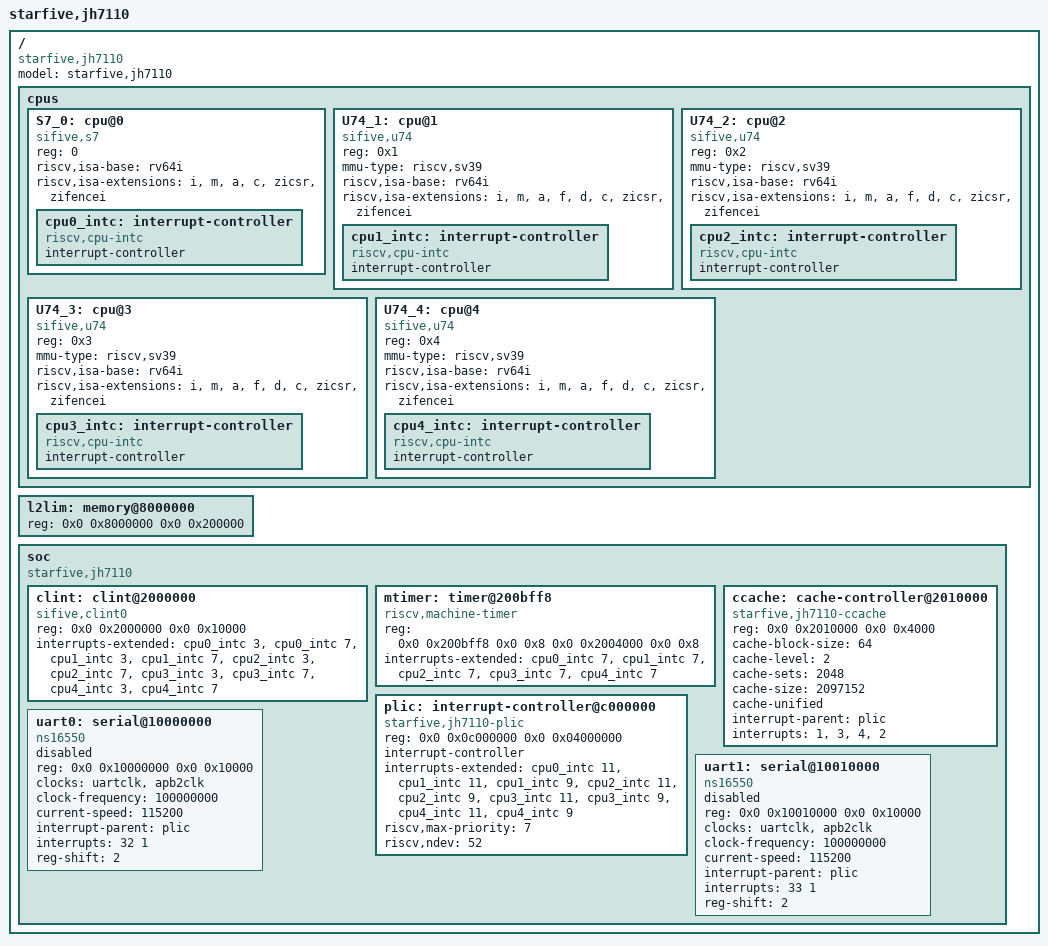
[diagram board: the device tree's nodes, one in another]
/*
 * Copyright (c) 2024 Pratik Farkase <pratik.farkase@wsisweden.com>
 * Copyright (c) 2024 Sigma Connectivity WSI AB
 *
 * SPDX-License-Identifier: Apache-2.0
 */

#include "jh7110-clk.dtsi"
#include <zephyr/dt-bindings/gpio/gpio.h>
#include <freq.h>

/ {
	compatible = "starfive,jh7110";
	#address-cells = <2>;
	#size-cells = <2>;
	model = "starfive,jh7110";

	cpus {
		#address-cells = <1>;
		#size-cells = <0>;

		S7_0: cpu@0 {
			compatible = "sifive,s7", "riscv";
			reg = <0>;
			device_type = "cpu";
			riscv,isa-base = "rv64i";
			riscv,isa-extensions = "i", "m", "a", "c", "zicsr", "zifencei";
			status = "okay";

			cpu0_intc: interrupt-controller {
				compatible = "riscv,cpu-intc";
				interrupt-controller;
				#interrupt-cells = <1>;
			};
		};

		U74_1: cpu@1 {
			compatible = "sifive,u74", "riscv";
			reg = <0x1>;
			device_type = "cpu";
			mmu-type = "riscv,sv39";
			riscv,isa-base = "rv64i";
			riscv,isa-extensions = "i", "m", "a", "f", "d", "c", "zicsr", "zifencei";

			cpu1_intc: interrupt-controller {
				compatible = "riscv,cpu-intc";
				#interrupt-cells = <1>;
				interrupt-controller;
			};
		};

		U74_2: cpu@2 {
			compatible = "sifive,u74", "riscv";
			reg = <0x2>;
			device_type = "cpu";
			mmu-type = "riscv,sv39";
			riscv,isa-base = "rv64i";
			riscv,isa-extensions = "i", "m", "a", "f", "d", "c", "zicsr", "zifencei";

			cpu2_intc: interrupt-controller {
				compatible = "riscv,cpu-intc";
				#interrupt-cells = <1>;
				interrupt-controller;
			};
		};

		U74_3: cpu@3 {
			compatible = "sifive,u74", "riscv";
			reg = <0x3>;
			device_type = "cpu";
			mmu-type = "riscv,sv39";
			riscv,isa-base = "rv64i";
			riscv,isa-extensions = "i", "m", "a", "f", "d", "c", "zicsr", "zifencei";

			cpu3_intc: interrupt-controller {
				compatible = "riscv,cpu-intc";
				#interrupt-cells = <1>;
				interrupt-controller;
			};
		};

		U74_4: cpu@4 {
			compatible = "sifive,u74", "riscv";
			reg = <0x4>;
			device_type = "cpu";
			mmu-type = "riscv,sv39";
			riscv,isa-base = "rv64i";
			riscv,isa-extensions = "i", "m", "a", "f", "d", "c", "zicsr", "zifencei";

			cpu4_intc: interrupt-controller {
				compatible = "riscv,cpu-intc";
				#interrupt-cells = <1>;
				interrupt-controller;
			};
		};
	};

	l2lim: memory@8000000 {
		reg = <0x0 0x8000000 0x0 0x200000>;
		device_type = "memory";
	};

	soc {
		compatible = "starfive,jh7110", "simple-bus";
		ranges;
		#address-cells = <2>;
		#size-cells = <2>;
		#clock-cells = <1>;

		clint: clint@2000000 {
			compatible = "sifive,clint0";
			reg = <0x0 0x2000000 0x0 0x10000>;
			interrupts-extended = <&cpu0_intc 3 &cpu0_intc 7
					       &cpu1_intc 3 &cpu1_intc 7
					       &cpu2_intc 3 &cpu2_intc 7
					       &cpu3_intc 3 &cpu3_intc 7
					       &cpu4_intc 3 &cpu4_intc 7>;
		};

		mtimer: timer@200bff8 {
			compatible = "riscv,machine-timer";
			reg = <0x0 0x200bff8 0x0 0x8 0x0 0x2004000 0x0 0x8>;
			interrupts-extended = <&cpu0_intc 7
					       &cpu1_intc 7
					       &cpu2_intc 7
					       &cpu3_intc 7
					       &cpu4_intc 7>;
			reg-names = "mtime", "mtimecmp";
		};

		ccache: cache-controller@2010000 {
			compatible = "starfive,jh7110-ccache", "sifive,ccache0", "cache";
			reg = <0x0 0x2010000 0x0 0x4000>;
			cache-block-size = <64>;
			cache-level = <2>;
			cache-sets = <2048>;
			cache-size = <2097152>;
			cache-unified;
			interrupt-parent = <&plic>;
			interrupts = <1>, <3>, <4>, <2>;
		};

		plic: interrupt-controller@c000000 {
			compatible = "starfive,jh7110-plic", "sifive,plic-1.0.0";
			reg = <0x0 0x0c000000 0x0 0x04000000>;
			#address-cells = <0>;
			#interrupt-cells = <2>;
			interrupt-controller;
			interrupts-extended = <&cpu0_intc 11>,
					      <&cpu1_intc 11>, <&cpu1_intc 9>,
					      <&cpu2_intc 11>, <&cpu2_intc 9>,
					      <&cpu3_intc 11>, <&cpu3_intc 9>,
					      <&cpu4_intc 11>, <&cpu4_intc 9>;
			riscv,max-priority = <7>;
			riscv,ndev = <52>;
		};

		uart0: serial@10000000 {
			compatible = "ns16550", "snps,dw-apb-uart";
			reg = <0x0 0x10000000 0x0 0x10000>;
			clocks = <&uartclk>, <&apb2clk>;
			clock-names = "baudclk", "apb_pclk";
			clock-frequency = <100000000>;
			current-speed = <115200>;
			interrupt-parent = <&plic>;
			interrupts = <32 1>;
			reg-shift = <2>;
			status = "disabled";
		};

		uart1: serial@10010000 {
			compatible = "ns16550", "snps,dw-apb-uart";
			reg = <0x0 0x10010000 0x0 0x10000>;
			clocks = <&uartclk>, <&apb2clk>;
			clock-names = "baudclk", "apb_pclk";
			clock-frequency = <100000000>;
			current-speed = <115200>;
			interrupt-parent = <&plic>;
			interrupts = <33 1>;
			reg-shift = <2>;
			status = "disabled";
		};
	};
};
